# nrf54l15_application register map
Vendor: Nordic Semiconductor; Series: nrf54l; File version: 1
CPU: CM33 r0p4, little endian, MPU, FPU, 3 interrupt priority bits, 270 interrupts, 4 SAU regions
Registers are 32-bit, read-write, reset 0x0 unless marked. A register's access mark holds for its fields unless they carry their own. Offsets are from the block's base; [hi:lo] are bit positions; lines under a group give offsets from that group; {n}, {i} and the like mark numbered series; 'fields as' and 'values as' point back to an identical list.

## GLOBAL_REGULATORS_NS — Voltage regulators 0
Base 0x40120000; alternate view of GLOBAL_OSCILLATORS_NS
Same registers: GLOBAL_REGULATORS_S 0x50120000 (alternate view of GLOBAL_OSCILLATORS_S)
0x400 VREGM group — Register interface for the medium voltage regulator
  0x00 ENABLE reset 0x1 — Enable register for VREGM
    [0] ENABLE — Enable the regulator
      0=Disabled (Disable the regulator); 1=Enabled (Enable the regulator)
  0x10 VOLT — Set output voltage
    [2:0] VOLT
      0=2V6 (2.6 V); 1=2V7 (2.7 V); 2=2V8 (2.8 V); 3=2V9 (2.9 V); 4=3V0 (3.0 V); 5=3V1 (3.1 V); 6=3V2 (3.2 V); 7=3V3 (3.3 V)
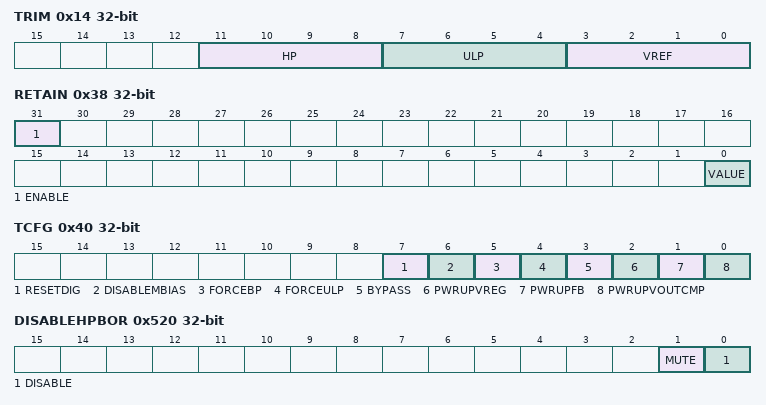
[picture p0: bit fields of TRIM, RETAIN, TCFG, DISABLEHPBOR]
  0x14 TRIM — Unspecified
    [11:8] HP — VOUT
    [7:4] ULP — VOUTCOMP TH ie Refresh Ripple
    [3:0] VREF — VFREF_MBIAS
  0x30 READY ro — Unspecified
    [0] READY — Regulator ready
  0x34 BPREADY ro — Unspecified
    [0] BPREADY — Bypass mode flag
  0x38 RETAIN — Override the retention control signal to the regulator for testing.
    [31] ENABLE — Override enable
    [0] VALUE — Override value
  0x3C DTBCFG — Unspecified
    [2:0] DTB0CFG — Using 3 bits of DTB0CFG allows to hook four internal signals to DTB. VOUTCMP is needed for test but others are free choice for debug.
      4=VOUTCOMP (Unspecified); 5=PWRUPFB (Unspecified); 6=PWRUPVREG (Unspecified); 7=BYPASS (Unspecified)
  0x40 TCFG — Unspecified
    [7] RESETDIG — Isolates DIG_CORE outputs to 0
    [6] DISABLEMBIAS — Blocks MBIAS_READY
    [5] FORCEBP — Forces AFSM to run HP (when requested) ie blocks BP
    [4] FORCEULP — Forces AFSM to run ULP refresh ie blocks HP and BP
    [3] BYPASS — Override BYPASS on by OR-gate
    [2] PWRUPVREG — Override PWRUP_VREG on by OR-gate
    [1] PWRUPFB — Override PWRUP_FB on by OR-gate
    [0] PWRUPVOUTCMP — Override PWRUP_VOUTCMP on by OR-gate
0x500 SYSTEMOFF wo
  [0] SYSTEMOFF — Enable System OFF mode
    1=Enter (Enable System OFF mode)
0x504 SYSTEMOFFCFG — Configure SystemOff
  [0] GRTCWAIT — Enabled waiting for GRTC sleep acknowledge before entering SystemOff
    0=Disabled (Do not wait for GRTC sleep); 1=Enabled (Wait for GRTC sleep)
0x520 DISABLEHPBOR wo — Enable or disable HPBOR
  [1] MUTE — Mute or unmute HPBOR
    0=Unmuted (Unmute HPBOR); 1=Muted (Mute HPBOR)
  [0] DISABLE — Enable or disable HPBOR
    0=Enabled (Enable HPBOR); 1=Disabled (Disable HPBOR)
0x524 BIASREQUEST — Request BIAS module
  [0] REQ
    0=Automatic (Bias is requested automatically by users); 1=Requested (Bias is always requested)
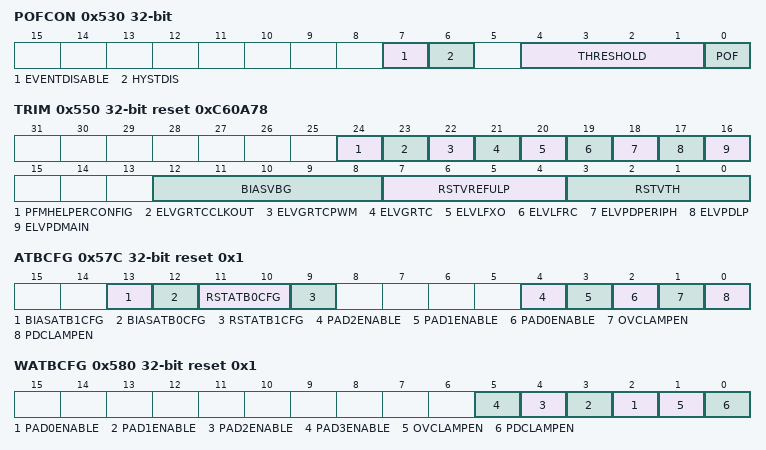
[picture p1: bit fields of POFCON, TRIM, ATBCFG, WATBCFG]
0x530 POFCON — Power-fail comparator configuration
  [7] EVENTDISABLE — Disable the POFWARN power-fail warning event
    0=Enabled (POFWARN event is generated); 1=Disabled (POFWARN event is not generated)
  [6] HYSTDIS — Bypass power-fail comparator hysteresis
    0=Normal (Hysteresis active); 1=NoHyst (Hysteresis disabled)
  [4:1] THRESHOLD — Power-fail comparator threshold setting
    0=V17 (Set threshold to 1.7 V for VDD); 1=V18 (Set threshold to 1.8 V for VDD); 2=V19 (Set threshold to 1.9 V for VDD); 3=V20 (Set threshold to 2.0 V for VDD); 4=V21 (Set threshold to 2.1 V for VDD); 5=V22 (Set threshold to 2.2 V for VDD); 6=V23 (Set threshold to 2.3 V for VDD); 7=V24 (Set threshold to 2.4 V for VDD); 8=V25 (Set threshold to 2.5 V for VDD); 9=V26 (Set threshold to 2.6 V for VDD); 10=V27 (Set threshold to 2.7 V for VDD); 11=V28 (Set threshold to 2.8 V for VDD); 12=V29 (Set threshold to 2.9 V for VDD); 13=V30 (Set threshold to 3.0 V for VDD); 14=V31 (Set threshold to 3.1 V for VDD); 15=V32 (Set threshold to 3.2 V for VDD)
  [0] POF — Enable or disable power-fail comparator
    0=Disabled; 1=Enabled
0x534 POFSTAT ro — Power-fail comparator status register
  [0] COMPARATOR — Power-fail comparator status
    0=Above (Voltage detected above VPOF threshold); 1=Below (Voltage detected below VPOF threshold)
0x550 TRIM reset 0xC60A78 — TRIM values
  [24] PFMHELPERCONFIG — Condition for enabling PFM helper mode
    0=Default (Request helper mode when PLL HF output is requested.); 1=Conservative (Request helper mode when PLL HF output or PD_MCU are requested.)
  [23] ELVGRTCCLKOUT — Allow or prevent ELV mode when GRTC CKOUT is active
    0=Allow ELV mode when GRTC CKOUT is active; 1=Prevent ELV mode when GRTC CKOUT is active
  [22] ELVGRTCPWM — Allow or prevent ELV mode when GRTC PWM is active
    0=Allow ELV mode when GRTC PWM is active; 1=Prevent ELV mode when GRTC PWM is active
  [21] ELVGRTC — Allow or prevent ELV mode when GRTC core is active
    0=Allow ELV mode when GRTC core is active; 1=Prevent ELV mode when GRTC core is active
  [20] ELVLFXO — Allow or prevent ELV mode when LFXO is ON
    0=Allow ELV mode when LFXO is ON; 1=Prevent ELV mode when LFXO is ON
  [19] ELVLFRC — Allow or prevent ELV mode when LFRC is ON
    0=Allow ELV mode when LFRC is ON; 1=Prevent ELV mode when LFRC is ON
  [18] ELVPDPERIPH — Allow or prevent ELV mode when PD_PERIPH is ON
    0=Allow ELV mode when PD_PERIPH is ON; 1=Prevent ELV mode when PD_PERIPH is ON
  [17] ELVPDLP — Allow or prevent ELV mode when PD_LP is ON
    0=Allow ELV mode when PD_LP is ON; 1=Prevent ELV mode when PD_LP is ON
  [16] ELVPDMAIN — Allow or prevent ELV mode when PD_MAIN is ON
    0=Allow ELV mode when PD_MAIN is ON; 1=Prevent ELV mode when PD_MAIN is ON
  [12:8] BIASVBG — Master bias bandgap trim
  [7:4] RSTVREFULP — Trim value of VREF_ULP
  [3:0] RSTVTH — Threshold trim, power-on reset
0x57C ATBCFG reset 0x1 — Analog test bus control
  [13] BIASATB1CFG — Connect or disconnect MBIAS to analog test bus
    0=Disconnect from analog test bus; 1=Connect IBPSR_8U current to ATB1
  [12] BIASATB0CFG — Connect or disconnect MBIAS to analog test bus
    0=Disconnect from analog test bus; 1=Connect VBG voltage to ATB0
  [11:10] RSTATB0CFG — Configure connection of RST to analog test bus
    0=Disconnect from analog test bus; 1=VREF_ULP connected to ATB0; 2=AVDD_DIV2 connected to ATB0; 3=VBG_RST connected to ATB0
  [9] RSTATB1CFG — Configure connection of RST to analog test bus
    0=Disconnect from analog test bus; 1=Connect (IBPP connected to ATB1)
  [4] PAD2ENABLE — Enable or disable ATB2 pad
    0=Disabled (Disable pad); 1=Enable pad
  [3] PAD1ENABLE — Enable or disable ATB1 pad
    0=Disabled (Disable pad); 1=Enable pad
  [2] PAD0ENABLE — Enable or disable ATB0 pad
    0=Disabled (Disable pad); 1=Enable pad
  [1] OVCLAMPEN — Enable or disable overvoltage clamp on ATB
    0=Disabled (Disable overvoltage clamp); 1=Enable overvoltage clamp
  [0] PDCLAMPEN — Enable or disable power-down clamp on ATB
    0=Disable power-down clamp; 1=Enable power-down clamp
0x580 WATBCFG reset 0x1 — WATB control
  [n+2] PAD{n}ENABLE (n=0..3) — Enable or disable WATB{n} pad
    0=Disabled (Disable pad); 1=Enable pad
  [1] OVCLAMPEN — Enable or disable overvoltage clamp on WATB
    values as ATBCFG.OVCLAMPEN
  [0] PDCLAMPEN — Enable or disable power-down clamp on WATB
    0=Disable power-down clamp; 1=Enable power-down clamp
0x600 VREGMAIN group — Register interface for main voltage regulator.
  0x00 DCDCEN — Enable DC/DC converter for better power efficiency
    [0] VAL — Enable DC/DC buck converter
      0=Disable DC/DC converter and use LDO; 1=Enable DC/DC converter
  0x04 INDUCTORDET ro — VREGMAIN inductor detection
    [0] DETECTED
      0=InductorNotDetected (VREGMAIN inductor not detected); 1=InductorDetected (VREGMAIN inductor detected)
  0x08 STATUS ro — Voltage regulator status
    [6:0] MODE — Current voltage regulator mode
      9=Ldo (Linear low drop output mode - a high power, low efficiency mode); 10=Pfm (Pulse frequency modulation mode - a low power, high efficiency mode); 12=Pwm (Pulse width modulation mode - a high power, high efficiency, and clean power (low noise) mode); 8=Ext (External supply mode); 1=Reset mode; 41=ExtLdo (Transition state between EXT to LDO); 11=PfmLdo (Transition state between PFM to LDO); 13=LdoPwm (Transition state between LDO and PWM); 14=PfmPwm (Transition state between PFM to PWM); 46=PwmPfm (Transition state between PWM to PFM); 28=PwmIcmp (Transition state between PWM to PWM_PFM, where the FSM waits for the PWM ICMP)
  0x0C PFMICMPRUNNING ro — Current PFM ICMP status
    [0] TIMERRUNNING
      0=NotRunning (PFM ICMP timer is not running); 1=Running (PFM ICMP timer is running)
  0x10 PFMICMPFLAG — PFM ICMP has been triggered
    [0] PFMICMPFLAG write-1-clears
      0=NotTriggered (PFM ICMP has not been triggered); 1=Triggered (PFM ICMP has been triggered)
  0x14 BUCKLSCOUNT ro — Read counter output controlling low-side current threshold for PFM mode
    [4:0] BUCKLSCOUNT
  0x18 CONFIG group — Configure the MMI behavior
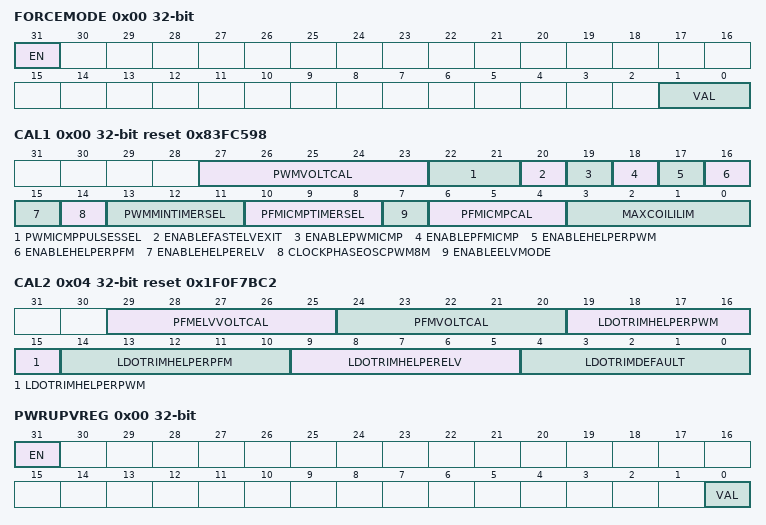
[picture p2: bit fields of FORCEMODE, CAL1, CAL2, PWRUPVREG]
    0x00 FORCEMODE — Force the MMI into a certain mode. The Force Mode is NOT retained through SystemOff. If External mode is required through SystemOff, please refer to REQUESTEXTERNAL register.
      [31] EN — Enable force mode for the regulator
        0=Disabled (Force mode is disabled); 1=Enabled (Force mode is enabled)
      [1:0] VAL — Current voltage regulator mode
        0=Ext (Force to external supply mode); 1=Ldo (Force to LDO mode); 2=Pfm (Force to PFM mode); 3=Pwm (Force to PWM mode)
    0x04 REQUESTEXTERNAL — Request external mode, and switch OFF the regulator This request is retain through SystemOff
      [0] VAL — Request external mode for the regulator
        0=Disabled (External mode is not requested); 1=Enabled (External mode is requested)
    0x08 VREGENLOAD — Enable test load for P_LR0V9 pad
      [0] VAL
        0=NormalOperation (No load); 1=TestLoad (88 Ohm test load, about 10mA load current at 0.9V)
    0x0C BUCKSETLSCOUNTER — Force the counter in the zero-cross detector to the set value for PFM mode. Setting MSB high (5) enables forcing using the first five bits (4:0). If MSB is low (5), the trim-code will be auto-calibrated in PFM with initial value 31.
      [5:0] BUCKSETLSCOUNTER
    0x10 DEBUGCONTROL — Analog module debug control signals
      [7:0] VAL
        0=Bit0 (Force ELV mode.); 1=Bit1 (Force resistive feedback in FB_DIV and REF_DIV.); 2=Bit2 (Enable comparator in BUCK_LP_PFM to turn off high-side driver.); 3=Bit3 (Force PWM_ICMP low.); 4=Bit4 (Force PFM_ICMP low.); 5=Bit5 (Disable LDO current limiter in all helper modes.); 6=Bit6 (Disable fast discharge in ELV-exit.); 7=Bit7 (Disable counter counting PFM pulses during ELV exit.)
    0x14 ATB0CFG — Analog testbus 0 configuration
      [3:0] ATB0CFG
        0=HiZ (Allow other IPs to use ATB0); 8=VregBg (VREG bandgap voltage); 9=PwmErrAmp (Output of PWM error amplifier); 10=PwmBg (PWM bandgap voltage); 11=PfmRevDiv (Reference divider inside PFM); 12=PDccVddAO3V0 (Internal VDD_AO_3V0 for P_DCC and force PMOS in output driver ON); 13=PDccVss (Internal VSS for P_DCC and force NMOS in output driver ON); 14=VddAna0V9; 15=VddDig0V9
    0x18 ATB1CFG — Analog testbus 1 configuration
      [3:0] ATB1CFG
        0=HiZ (Allow other IPs to use ATB1); 8=HiZ8 (Allow other IPs to use ATB1); 9=PwrMltVss (Internal VSS for POWER_MLT); 10=PDccIndPin (P_DCC inductor pin); 11=PfmFbDiv (Feedback divider inside PFM); {v}=HiZ{v} (Allow other IPs to use ATB1) (v=12..15)
    0x1C DTB0CFG — Digital testbus 0 configuration
      [2:0] DTB0CFG
        0=Dtb0Low (Allow other IPs to use DTB0); 1=BuckLsIlim0V9-Low-side limiter/zero-cross comparator output; 2=VoutCmp0V9_CMP_0V9; 3=AFSM_S0_0V9 – LSB for ELV state machine; {v}=Dtb0Low{v} (Reserved, allow other IPs to use DTB0) (v=4..7)
    0x20 DTB1CFG — Digital testbus 1 configuration
      [2:0] DTB1CFG
        0=Dtb1Low0 (Allow other IPs to use DTB1); 1=BUCK_HS_ILIM_0V9 – High-side limiter comparator output; 2=BUCK_PFM_ICMP – PFM over-current comparator output; 3=AFSM_S1_0V9 – MSB for ELV state machine; {v}=Dtb1Low{v} (Reserved, allow other IPs to use DTB1) (v=4..7)
  0x3C CALIBRATION group — Calibration values written from FICR
    0x00 CAL1 reset 0x83FC598 — Unspecified
      [27:23] PWMVOLTCAL — Calibration of BUCK_LP_PWM output voltage
      [22:21] PWMICMPPULSESSEL — Configure the number of PWM ICMP pulses to count before switching back to PFM. The counter can be configured with 32 (4us) and 64 (8us) pulse count for n=1,2 respectively. The counter can disabled with n=0. The value n=3, is not a valid configuration.
      [20] ENABLEFASTELVEXIT — Enable fast exit from ELV. This must be enabled along with the ENABLEHELPERELV
        0=Disabled (Fast exit is disabled); 1=Enabled (Fast exit is enabled)
      [19] ENABLEPWMICMP — Enable PWM ICMP (to auto detect no high load current is present)
        0=Disabled (PWM ICMP is disabled); 1=Enabled (PWM ICMP is enabled)
      [18] ENABLEPFMICMP — Enable PFM ICMP (to auto detect high load)
        0=Disabled (PFM ICMP is disabled); 1=Enabled (PFM ICMP is enabled)
      [17] ENABLEHELPERPWM — Enable helper mode in PWM mode (LDO will be powered ON)
        0=Disabled (PWM helper mode is disabled); 1=Enabled (PWM helper mode is enabled)
      [16] ENABLEHELPERPFM — Enable helper mode in PFM mode (LDO will be powered ON)
        0=Disabled (PFM helper mode is disabled); 1=Enabled (PFM helper mode is enabled)
      [15] ENABLEHELPERELV — Enable fast exit from ELV (helper mode in ELV, LDO will be powered ON)
        0=Disabled (ELV helper mode ELV is disabled); 1=Enabled (ELV helper mode is enabled)
      [14] CLOCKPHASEOSCPWM8M — Configure the phase of the generated DCDC clock (for PWM mode) with respect to the system clock, 0 in phase and 1 is out of phase
        0=InPhase; 1=OutOfPhase
      [13:11] PWMMINTIMERSEL — Configure the minimum time to stay in PWM mode after a PWM mode request. The timer has a minimum value of 32us and maximum value of 256us, with linear increments of 32us (32us, 64us, 96us, etc..). The timer has 3 bits to select the timer value (n), where time = 32*(n + 1) us.
      [10:8] PFMICMPTIMERSEL — Configure the time to stay in PWM mode after a PFM ICMP request. The timer has a minimum value of 32us and maximum value of 2ms, with exponential increments (32us, 64us, 128us, etc..). The timer has 3 bits to select the time value (n), where time = 32*(2^n) us. The value n=7, is not a valid configuration.
      [7] ENABLEELVMODE — Enable ELV mode (Extreme Low Voltage) to be automatically switched to in PFM mode if there is no power requests
      [6:4] PFMICMPCAL — Calibration of PFM mode overcurrent comparator through duty cycle control (twos complement)
      [3:0] MAXCOILILIM — Set coil current limit to avoid core saturation
    0x04 CAL2 reset 0x1F0F7BC2 — Unspecified
      [29:25] PFMELVVOLTCAL — Calibration of ELV output voltage
      [24:20] PFMVOLTCAL — Calibration of BUCK_LP_PFM output voltage
      [19:15] LDOTRIMHELPERPWM — Calibration of LDO reference voltage for PWM helper mode operation, 2nd complement
      [14:10] LDOTRIMHELPERPFM — Calibration of LDO reference voltage for PFM helper mode operation, 2nd complement
      [9:5] LDOTRIMHELPERELV — Calibration of LDO reference voltage for ELV helper mode operation, 2nd complement
      [4:0] LDOTRIMDEFAULT — Calibration of LDO reference voltage for normal operation, 2nd complement
  0x44 OVERRIDE group — Override analog IP signals
    0x00 PWRUPVREG — Override the PWRUP signal for LDO (Vreg) to the analog module
      [31] EN — Enable the override
        0=Disabled (Override is disabled); 1=Enabled (Override is enabled)
      [0] VAL — Override value
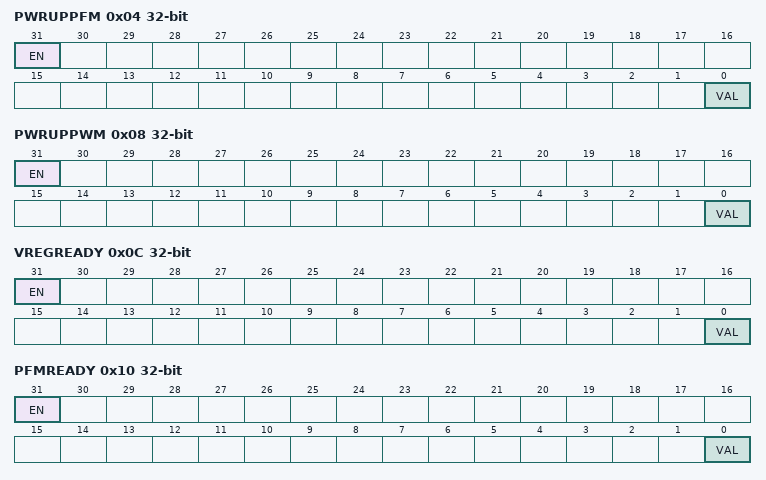
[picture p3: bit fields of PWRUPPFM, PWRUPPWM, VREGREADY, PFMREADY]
    0x04 PWRUPPFM — Override the PWRUP signal for PFM to the analog module
      fields as VREGMAIN.OVERRIDE.PWRUPVREG
    0x08 PWRUPPWM — Override the PWRUP signal for PWM to the analog module
      fields as VREGMAIN.OVERRIDE.PWRUPVREG
    0x0C VREGREADY — Override the Ready signal of LDO (Vreg) from the analog module
      fields as VREGMAIN.OVERRIDE.PWRUPVREG
    0x10 PFMREADY — Override the Ready signal of PFM from the analog module
      fields as VREGMAIN.OVERRIDE.PWRUPVREG
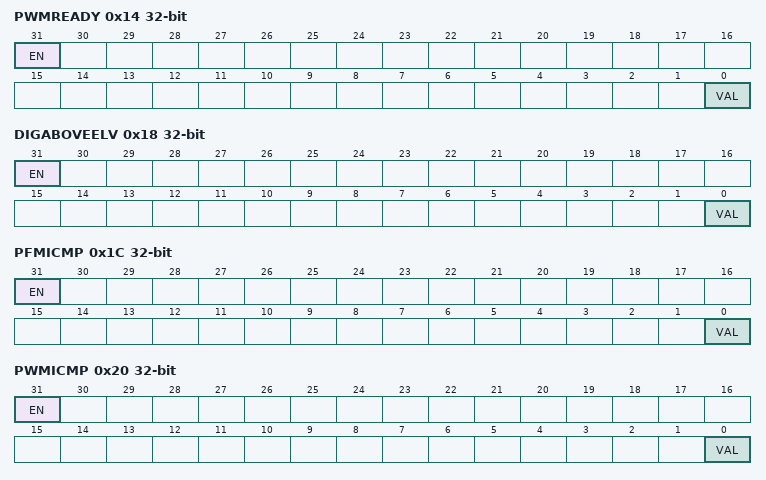
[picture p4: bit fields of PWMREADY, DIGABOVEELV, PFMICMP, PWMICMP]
    0x14 PWMREADY — Override the Ready signal of PWM from the analog module
      fields as VREGMAIN.OVERRIDE.PWRUPVREG
    0x18 DIGABOVEELV — Override the pwrAboveElv signal from the analog module
      [31] EN — Enable the override
        values as VREGMAIN.OVERRIDE.PWRUPVREG.EN
      [0] VAL — Override value for the signal
    0x1C PFMICMP — Override the PfmIcmp signal from the analog module
      [31] EN — Enable the override
        values as VREGMAIN.OVERRIDE.PWRUPVREG.EN
      [0] VAL — Current value of the signal
    0x20 PWMICMP — Override the PwmIcmp signal from the analog module
      fields as VREGMAIN.OVERRIDE.PFMICMP
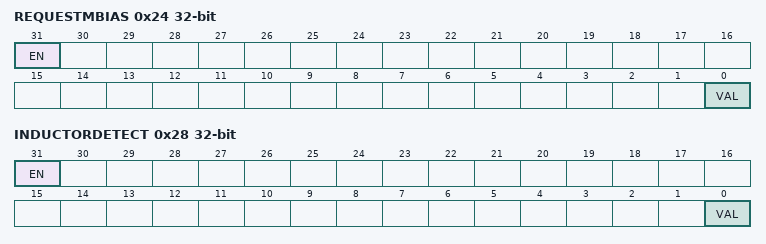
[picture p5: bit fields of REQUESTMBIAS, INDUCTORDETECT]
    0x24 REQUESTMBIAS — Override the requestMbias_a signal from the MMI
      [31] EN — Enable the override
        values as VREGMAIN.OVERRIDE.PWRUPVREG.EN
      [0] VAL — Override value of the signal
    0x28 INDUCTORDETECT — Override the Buck Inductor Detected signal from the analog module
      fields as VREGMAIN.OVERRIDE.PFMICMP
